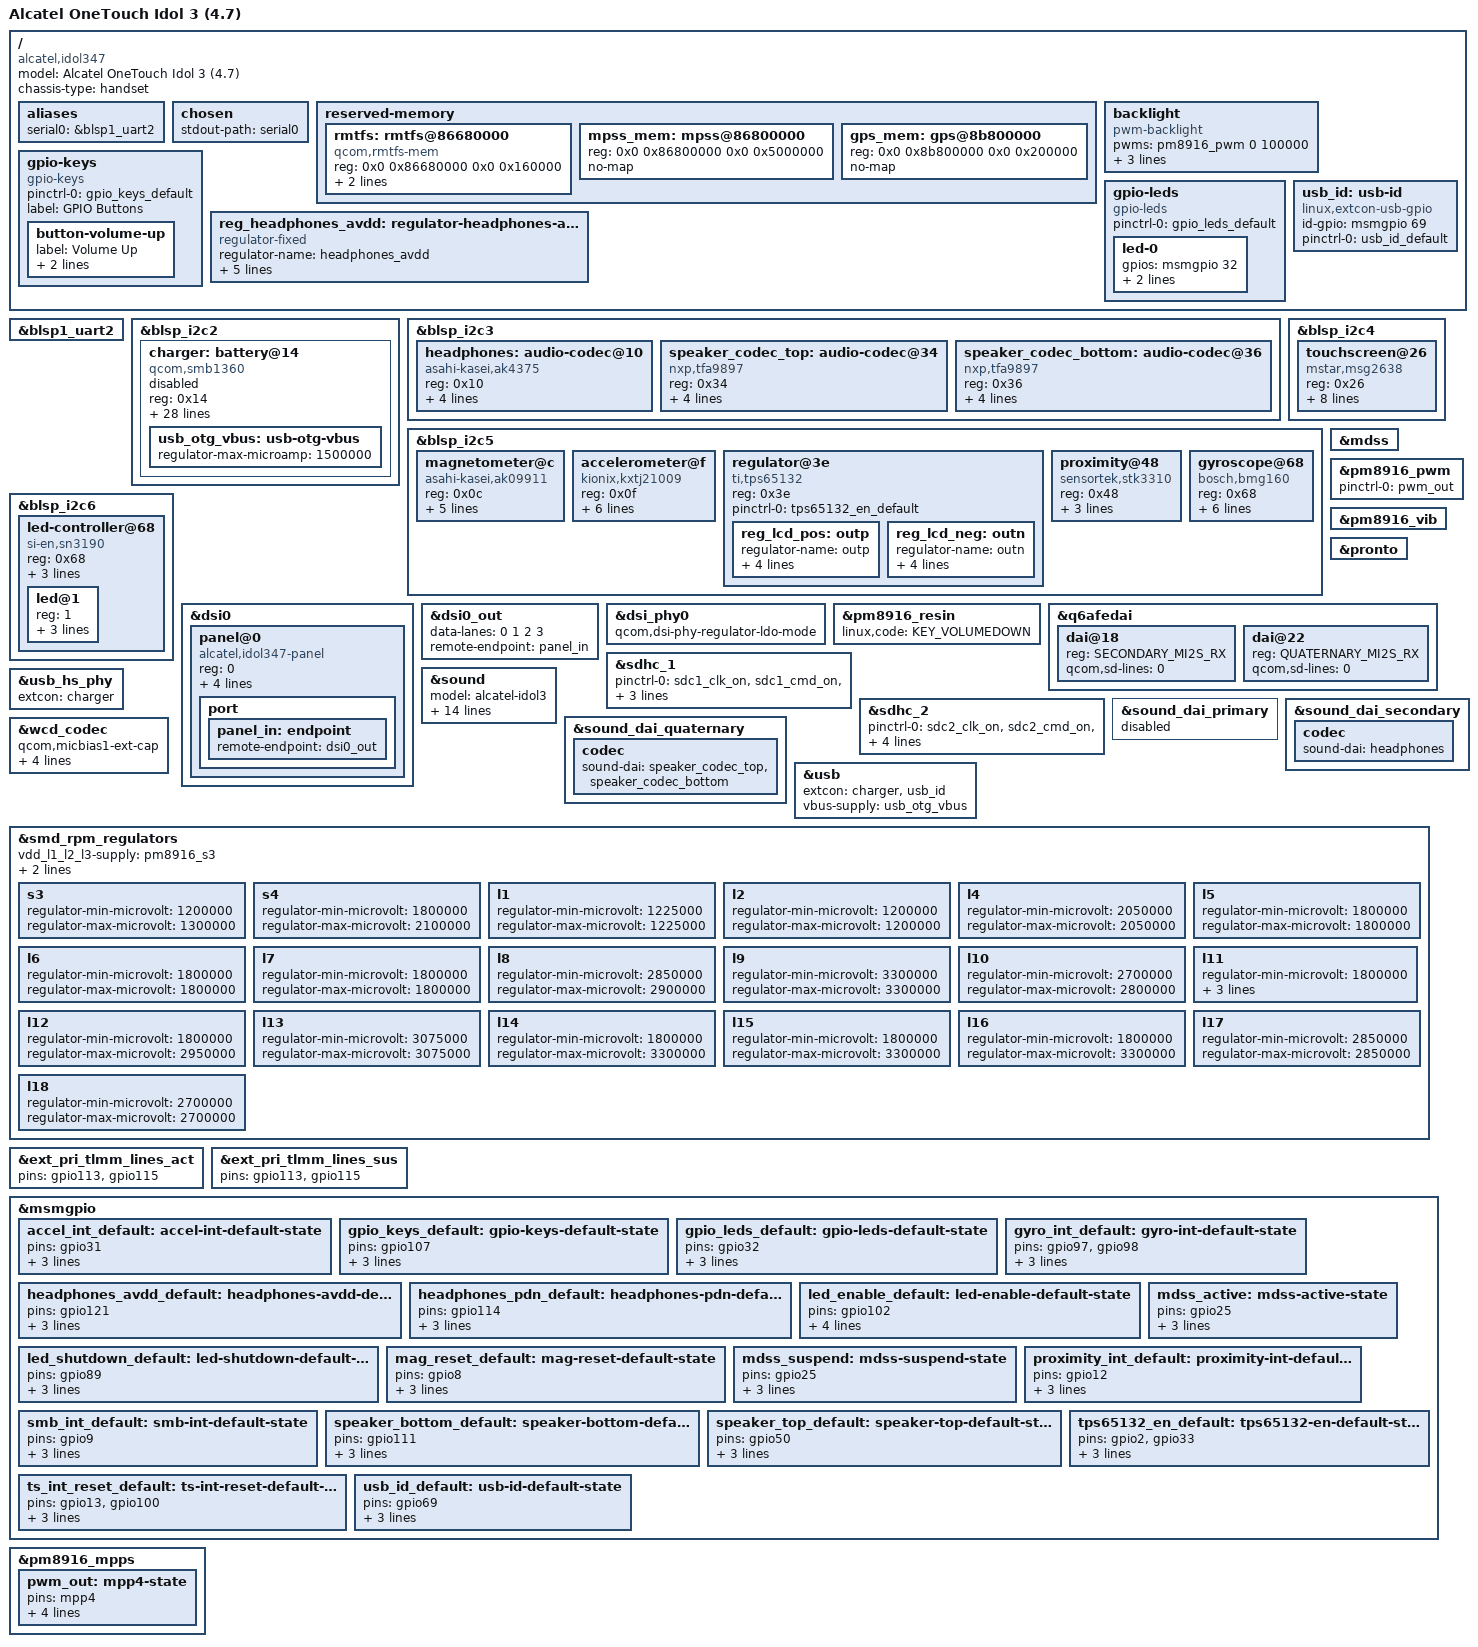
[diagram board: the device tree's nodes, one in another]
// SPDX-License-Identifier: GPL-2.0-only

/dts-v1/;

#include "msm8916-pm8916.dtsi"
#include "msm8916-modem.dtsi"

#include <dt-bindings/gpio/gpio.h>
#include <dt-bindings/input/input.h>
#include <dt-bindings/leds/common.h>
#include <dt-bindings/pinctrl/qcom,pmic-mpp.h>

/ {
	model = "Alcatel OneTouch Idol 3 (4.7)";
	compatible = "alcatel,idol347", "qcom,msm8916";
	chassis-type = "handset";

	aliases {
		serial0 = &blsp1_uart2;
	};

	chosen {
		stdout-path = "serial0";
	};

	reserved-memory {
		/delete-node/ rmtfs@86700000;
		/delete-node/ reserved@86680000;

		rmtfs: rmtfs@86680000 {
			compatible = "qcom,rmtfs-mem";
			reg = <0x0 0x86680000 0x0 0x160000>;
			no-map;

			qcom,client-id = <1>;
		};

		mpss_mem: mpss@86800000 {
			reg = <0x0 0x86800000 0x0 0x5000000>;
			no-map;
		};

		gps_mem: gps@8b800000 {
			reg = <0x0 0x8b800000 0x0 0x200000>;
			no-map;
		};
	};

	backlight: backlight {
		compatible = "pwm-backlight";
		pwms = <&pm8916_pwm 0 100000>;

		brightness-levels = <0 255>;
		num-interpolated-steps = <255>;
		default-brightness-level = <64>;
	};

	gpio-keys {
		compatible = "gpio-keys";

		pinctrl-0 = <&gpio_keys_default>;
		pinctrl-names = "default";

		label = "GPIO Buttons";

		button-volume-up {
			label = "Volume Up";
			gpios = <&msmgpio 107 GPIO_ACTIVE_LOW>;
			linux,code = <KEY_VOLUMEUP>;
		};
	};

	gpio-leds {
		compatible = "gpio-leds";

		pinctrl-0 = <&gpio_leds_default>;
		pinctrl-names = "default";

		led-0 {
			gpios = <&msmgpio 32 GPIO_ACTIVE_HIGH>;
			linux,default-trigger = "torch";
			function = LED_FUNCTION_TORCH;
		};
	};

	reg_headphones_avdd: regulator-headphones-avdd {
		compatible = "regulator-fixed";
		regulator-name = "headphones_avdd";
		regulator-min-microvolt = <1800000>;
		regulator-max-microvolt = <1800000>;
		gpio = <&msmgpio 121 GPIO_ACTIVE_HIGH>;
		enable-active-high;
		pinctrl-0 = <&headphones_avdd_default>;
		pinctrl-names = "default";
	};

	usb_id: usb-id {
		compatible = "linux,extcon-usb-gpio";
		id-gpio = <&msmgpio 69 GPIO_ACTIVE_HIGH>;
		pinctrl-0 = <&usb_id_default>;
		pinctrl-names = "default";
	};
};

&blsp1_uart2 {
	status = "okay";
};

&blsp_i2c2 {
	status = "okay";

	charger: battery@14 {
		compatible = "qcom,smb1360";
		reg = <0x14>;

		interrupt-parent = <&msmgpio>;
		interrupts = <9 IRQ_TYPE_LEVEL_LOW>;

		pinctrl-0 = <&smb_int_default>;
		pinctrl-names = "default";
		qcom,otp-rslow-config = /bits/ 8 <0x0 0x0 0x0 0x0>;

		qcom,float-voltage-mv = <4350>;
		qcom,iterm-ma = <75>;
		qcom,charging-timeout = <192>; /* 0 in downstream */
		qcom,recharge-thresh-mv = <100>;
		qcom,chg-inhibit-disabled;

		qcom,battery-profile = <0>;
		qcom,fg-batt-capacity-mah = <2000>;
		qcom,fg-cc-soc-coeff = <0x8819>;
		qcom,fg-cutoff-voltage-mv = <3400>;
		qcom,fg-ibatt-standby-ma = <200>;
		qcom,fg-cc-to-cv-mv = <4328>;
		qcom,thermistor-c1-coeff = <0x86C8>;
		qcom,fg-auto-recharge-soc = <95>; /* 99 in downstream */

		qcom,otp-hard-jeita-config;
		qcom,otp-hot-bat-decidegc = <550>;
		qcom,otp-cold-bat-decidegc = <0>;

		qcom,soft-jeita-config;
		qcom,warm-bat-decidegc = <450>;
		qcom,cool-bat-decidegc = <100>;
		qcom,soft-jeita-comp-voltage-mv = <4100>;
		qcom,soft-jeita-comp-current-ma = <550>;

		qcom,shdn-after-pwroff;
		qcom,fg-reset-at-pon;
		qcom,fg-reset-threshold-mv = <200>;

		/* Set by bootloader */
		status = "disabled";

		usb_otg_vbus: usb-otg-vbus {
			regulator-max-microamp = <1500000>;
		};
	};
};

&blsp_i2c3 {
	status = "okay";

	headphones: audio-codec@10 {
		compatible = "asahi-kasei,ak4375";
		reg = <0x10>;
		avdd-supply = <&reg_headphones_avdd>;
		tvdd-supply = <&pm8916_l6>;
		pdn-gpios = <&msmgpio 114 GPIO_ACTIVE_HIGH>;
		pinctrl-0 = <&headphones_pdn_default>;
		pinctrl-names = "default";
		#sound-dai-cells = <0>;
	};

	speaker_codec_top: audio-codec@34 {
		compatible = "nxp,tfa9897";
		reg = <0x34>;
		vddd-supply = <&pm8916_l6>;
		rcv-gpios = <&msmgpio 50 GPIO_ACTIVE_HIGH>;
		pinctrl-0 = <&speaker_top_default>;
		pinctrl-names = "default";
		sound-name-prefix = "Speaker Top";
		#sound-dai-cells = <0>;
	};

	speaker_codec_bottom: audio-codec@36 {
		compatible = "nxp,tfa9897";
		reg = <0x36>;
		vddd-supply = <&pm8916_l6>;
		rcv-gpios = <&msmgpio 111 GPIO_ACTIVE_HIGH>;
		pinctrl-0 = <&speaker_bottom_default>;
		pinctrl-names = "default";
		sound-name-prefix = "Speaker Bottom";
		#sound-dai-cells = <0>;
	};
};

&blsp_i2c4 {
	status = "okay";

	touchscreen@26 {
		compatible = "mstar,msg2638";
		reg = <0x26>;
		interrupt-parent = <&msmgpio>;
		interrupts = <13 IRQ_TYPE_EDGE_FALLING>;
		reset-gpios = <&msmgpio 100 GPIO_ACTIVE_LOW>;
		pinctrl-0 = <&ts_int_reset_default>;
		pinctrl-names = "default";
		vdd-supply = <&pm8916_l17>;
		vddio-supply = <&pm8916_l5>;
		touchscreen-size-x = <2048>;
		touchscreen-size-y = <2048>;
	};
};

&blsp_i2c5 {
	status = "okay";

	magnetometer@c {
		compatible = "asahi-kasei,ak09911";
		reg = <0x0c>;
		vdd-supply = <&pm8916_l17>;
		vid-supply = <&pm8916_l6>;
		reset-gpios = <&msmgpio 8 GPIO_ACTIVE_LOW>;
		pinctrl-0 = <&mag_reset_default>;
		pinctrl-names = "default";
		mount-matrix = "0", "1", "0",
			       "-1", "0", "0",
			       "0", "0", "1";
	};

	accelerometer@f {
		compatible = "kionix,kxtj21009";
		reg = <0x0f>;
		vdd-supply = <&pm8916_l17>;
		vddio-supply = <&pm8916_l6>;
		interrupt-parent = <&msmgpio>;
		interrupts = <31 IRQ_TYPE_EDGE_RISING>;
		pinctrl-0 = <&accel_int_default>;
		pinctrl-names = "default";
		mount-matrix = "-1", "0", "0",
			       "0", "1", "0",
			       "0", "0", "-1";
	};

	regulator@3e {
		compatible = "ti,tps65132";
		reg = <0x3e>;
		pinctrl-0 = <&tps65132_en_default>;
		pinctrl-names = "default";

		reg_lcd_pos: outp {
			regulator-name = "outp";
			regulator-min-microvolt = <5500000>;
			regulator-max-microvolt = <5500000>;
			enable-gpios = <&msmgpio 2 GPIO_ACTIVE_HIGH>;
			regulator-active-discharge = <1>;
		};

		reg_lcd_neg: outn {
			regulator-name = "outn";
			regulator-min-microvolt = <5500000>;
			regulator-max-microvolt = <5500000>;
			enable-gpios = <&msmgpio 33 GPIO_ACTIVE_HIGH>;
			regulator-active-discharge = <1>;
		};
	};

	proximity@48 {
		compatible = "sensortek,stk3310";
		reg = <0x48>;
		interrupt-parent = <&msmgpio>;
		interrupts = <12 IRQ_TYPE_EDGE_FALLING>;
		pinctrl-0 = <&proximity_int_default>;
		pinctrl-names = "default";
	};

	gyroscope@68 {
		compatible = "bosch,bmg160";
		reg = <0x68>;
		vdd-supply = <&pm8916_l17>;
		vddio-supply = <&pm8916_l6>;
		interrupt-parent = <&msmgpio>;
		interrupts = <97 IRQ_TYPE_EDGE_RISING>,
			     <98 IRQ_TYPE_EDGE_RISING>;
		pinctrl-0 = <&gyro_int_default>;
		pinctrl-names = "default";
	};
};

&blsp_i2c6 {
	status = "okay";

	led-controller@68 {
		compatible = "si-en,sn3190";
		reg = <0x68>;
		shutdown-gpios = <&msmgpio 89 GPIO_ACTIVE_HIGH>;
		pinctrl-0 = <&led_enable_default &led_shutdown_default>;
		pinctrl-names = "default";
		#address-cells = <1>;
		#size-cells = <0>;

		led@1 {
			reg = <1>;
			led-max-microamp = <5000>;
			function = LED_FUNCTION_INDICATOR;
			color = <LED_COLOR_ID_WHITE>;
		};
	};
};

&dsi0 {
	panel@0 {
		compatible = "alcatel,idol347-panel";
		reg = <0>;

		backlight = <&backlight>;

		vsp-supply = <&reg_lcd_pos>;
		vsn-supply = <&reg_lcd_neg>;

		reset-gpios = <&msmgpio 25 GPIO_ACTIVE_LOW>;

		port {
			panel_in: endpoint {
				remote-endpoint = <&dsi0_out>;
			};
		};
	};
};

&dsi0_out {
	data-lanes = <0 1 2 3>;
	remote-endpoint = <&panel_in>;
};

&dsi_phy0 {
	qcom,dsi-phy-regulator-ldo-mode;
};

&mdss {
	status = "okay";
};

&pm8916_pwm {
	pinctrl-0 = <&pwm_out>;
	pinctrl-names = "default";
	status = "okay";
};

&pm8916_resin {
	linux,code = <KEY_VOLUMEDOWN>;
	status = "okay";
};

&pm8916_vib {
	status = "okay";
};

&pronto {
	status = "okay";
};

&q6afedai {
	dai@18 {
		reg = <SECONDARY_MI2S_RX>;
		qcom,sd-lines = <0>;
	};

	dai@22 {
		reg = <QUATERNARY_MI2S_RX>;
		qcom,sd-lines = <0>;
	};
};

&sdhc_1 {
	pinctrl-0 = <&sdc1_clk_on &sdc1_cmd_on &sdc1_data_on>;
	pinctrl-1 = <&sdc1_clk_off &sdc1_cmd_off &sdc1_data_off>;
	pinctrl-names = "default", "sleep";

	status = "okay";
};

&sdhc_2 {
	pinctrl-0 = <&sdc2_clk_on &sdc2_cmd_on &sdc2_data_on &sdc2_cd_on>;
	pinctrl-1 = <&sdc2_clk_off &sdc2_cmd_off &sdc2_data_off &sdc2_cd_off>;
	pinctrl-names = "default", "sleep";

	cd-gpios = <&msmgpio 38 GPIO_ACTIVE_LOW>;

	status = "okay";
};

&sound {
	model = "alcatel-idol3";
	widgets =
		"Speaker", "Speaker Top",
		"Speaker", "Speaker Bottom";
	pin-switches = "Speaker Top", "Speaker Bottom";
	audio-routing =
		"Speaker Top", "Speaker Top OUT",
		"Speaker Bottom", "Speaker Bottom OUT",
		"AMIC1", "MIC BIAS External1",
		"AMIC2", "MIC BIAS Internal2",
		"AMIC3", "MIC BIAS External1";

	pinctrl-0 = <&cdc_pdm_lines_act &ext_pri_tlmm_lines_act &ext_pri_ws_act>,
		    <&ext_sec_tlmm_lines_act>;
	pinctrl-1 = <&cdc_pdm_lines_sus &ext_pri_tlmm_lines_sus &ext_pri_ws_sus>,
		    <&ext_sec_tlmm_lines_sus>;
	pinctrl-names = "default", "sleep";
	status = "okay";
};

&sound_dai_primary {
	status = "disabled";
};

&sound_dai_quaternary {
	status = "okay";

	codec {
		sound-dai = <&speaker_codec_top>, <&speaker_codec_bottom>;
	};
};

&sound_dai_secondary {
	status = "okay";

	codec {
		sound-dai = <&headphones>;
	};
};

&usb {
	extcon = <&charger>, <&usb_id>;
	vbus-supply = <&usb_otg_vbus>;
	status = "okay";
};

&usb_hs_phy {
	extcon = <&charger>;
};

&wcd_codec {
	qcom,micbias1-ext-cap;
	qcom,micbias-lvl = <2800>;
	qcom,mbhc-vthreshold-low = <75 100 120 180 500>;
	qcom,mbhc-vthreshold-high = <75 100 120 180 500>;
	qcom,hphl-jack-type-normally-open;
};

&smd_rpm_regulators {
	vdd_l1_l2_l3-supply = <&pm8916_s3>;
	vdd_l4_l5_l6-supply = <&pm8916_s4>;
	vdd_l7-supply = <&pm8916_s4>;

	s3 {
		regulator-min-microvolt = <1200000>;
		regulator-max-microvolt = <1300000>;
	};

	s4 {
		regulator-min-microvolt = <1800000>;
		regulator-max-microvolt = <2100000>;
	};

	l1 {
		regulator-min-microvolt = <1225000>;
		regulator-max-microvolt = <1225000>;
	};

	l2 {
		regulator-min-microvolt = <1200000>;
		regulator-max-microvolt = <1200000>;
	};

	l4 {
		regulator-min-microvolt = <2050000>;
		regulator-max-microvolt = <2050000>;
	};

	l5 {
		regulator-min-microvolt = <1800000>;
		regulator-max-microvolt = <1800000>;
	};

	l6 {
		regulator-min-microvolt = <1800000>;
		regulator-max-microvolt = <1800000>;
	};

	l7 {
		regulator-min-microvolt = <1800000>;
		regulator-max-microvolt = <1800000>;
	};

	l8 {
		regulator-min-microvolt = <2850000>;
		regulator-max-microvolt = <2900000>;
	};

	l9 {
		regulator-min-microvolt = <3300000>;
		regulator-max-microvolt = <3300000>;
	};

	l10 {
		regulator-min-microvolt = <2700000>;
		regulator-max-microvolt = <2800000>;
	};

	l11 {
		regulator-min-microvolt = <1800000>;
		regulator-max-microvolt = <2950000>;
		regulator-system-load = <200000>;
		regulator-allow-set-load;
	};

	l12 {
		regulator-min-microvolt = <1800000>;
		regulator-max-microvolt = <2950000>;
	};

	l13 {
		regulator-min-microvolt = <3075000>;
		regulator-max-microvolt = <3075000>;
	};

	l14 {
		regulator-min-microvolt = <1800000>;
		regulator-max-microvolt = <3300000>;
	};

	l15 {
		regulator-min-microvolt = <1800000>;
		regulator-max-microvolt = <3300000>;
	};

	l16 {
		regulator-min-microvolt = <1800000>;
		regulator-max-microvolt = <3300000>;
	};

	l17 {
		regulator-min-microvolt = <2850000>;
		regulator-max-microvolt = <2850000>;
	};

	l18 {
		regulator-min-microvolt = <2700000>;
		regulator-max-microvolt = <2700000>;
	};
};

/* Only some of the pins are used */
&ext_pri_tlmm_lines_act {
	pins = "gpio113", "gpio115";
};
&ext_pri_tlmm_lines_sus {
	pins = "gpio113", "gpio115";
};

&msmgpio {
	accel_int_default: accel-int-default-state {
		pins = "gpio31";
		function = "gpio";
		drive-strength = <2>;
		bias-disable;
	};

	gpio_keys_default: gpio-keys-default-state {
		pins = "gpio107";
		function = "gpio";
		drive-strength = <2>;
		bias-pull-up;
	};

	gpio_leds_default: gpio-leds-default-state {
		pins = "gpio32";
		function = "gpio";
		drive-strength = <2>;
		bias-disable;
	};

	gyro_int_default: gyro-int-default-state {
		pins = "gpio97", "gpio98";
		function = "gpio";
		drive-strength = <2>;
		bias-disable;
	};

	headphones_avdd_default: headphones-avdd-default-state {
		pins = "gpio121";
		function = "gpio";
		drive-strength = <2>;
		bias-disable;
	};

	headphones_pdn_default: headphones-pdn-default-state {
		pins = "gpio114";
		function = "gpio";
		drive-strength = <2>;
		bias-disable;
	};

	/*
	 * The OEM wired an additional GPIO to be asserted so that
	 * the si-en,sn3190 LED IC works. Since this GPIO is not
	 * part of the IC datasheet nor supported by the driver,
	 * force it asserted here.
	 */
	led_enable_default: led-enable-default-state {
		pins = "gpio102";
		function = "gpio";
		drive-strength = <2>;
		bias-disable;
		output-high;
	};

	led_shutdown_default: led-shutdown-default-state {
		pins = "gpio89";
		function = "gpio";
		drive-strength = <2>;
		bias-disable;
	};

	mag_reset_default: mag-reset-default-state {
		pins = "gpio8";
		function = "gpio";
		drive-strength = <2>;
		bias-disable;
	};

	mdss_active: mdss-active-state {
		pins = "gpio25";
		function = "gpio";
		drive-strength = <8>;
		bias-disable;
	};

	mdss_suspend: mdss-suspend-state {
		pins = "gpio25";
		function = "gpio";
		drive-strength = <2>;
		bias-pull-down;
	};

	proximity_int_default: proximity-int-default-state {
		pins = "gpio12";
		function = "gpio";
		drive-strength = <6>;
		bias-pull-up;
	};

	smb_int_default: smb-int-default-state {
		pins = "gpio9";
		function = "gpio";
		drive-strength = <2>;
		bias-pull-up;
	};

	speaker_bottom_default: speaker-bottom-default-state {
		pins = "gpio111";
		function = "gpio";
		drive-strength = <2>;
		bias-disable;
	};

	speaker_top_default: speaker-top-default-state {
		pins = "gpio50";
		function = "gpio";
		drive-strength = <2>;
		bias-disable;
	};

	tps65132_en_default: tps65132-en-default-state {
		pins = "gpio2", "gpio33";
		function = "gpio";
		drive-strength = <2>;
		bias-disable;
	};

	ts_int_reset_default: ts-int-reset-default-state {
		pins = "gpio13", "gpio100";
		function = "gpio";
		drive-strength = <2>;
		bias-disable;
	};

	usb_id_default: usb-id-default-state {
		pins = "gpio69";
		function = "gpio";
		drive-strength = <8>;
		bias-pull-up;
	};
};

&pm8916_mpps {
	pwm_out: mpp4-state {
		pins = "mpp4";
		function = "digital";
		power-source = <PM8916_MPP_L5>;
		output-low;
		qcom,dtest = <1>;
	};
};
